AUTOSAR XML (schema 3-2-1)
package /SeatHeater/SeatSensorLeft_swc
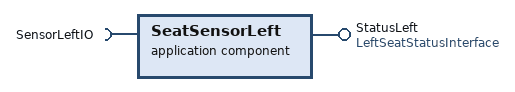
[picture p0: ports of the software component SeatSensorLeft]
  application software component type SeatSensorLeft
    provide port StatusLeft: unqueued-provider-com-spec{data-element=PassengerOnLeftSeat, alive-timeout=60.0}, provided-interface=LeftSeatStatusInterface
    require port SensorLeftIO
  internal behavior SeatSensorLeftBehavior: compontent=SeatSensorLeft
  swc implementation SeatSensorLeftImplementation: behavior=SeatSensorLeftBehavior
